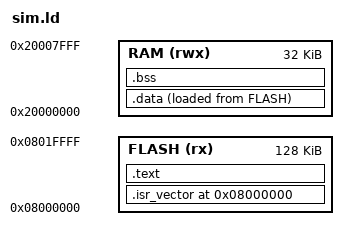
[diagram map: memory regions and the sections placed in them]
MEMORY
{
    FLASH (rx)  : ORIGIN = 0x08000000, LENGTH = 128K
    RAM   (rwx) : ORIGIN = 0x20000000, LENGTH = 32K
}

ENTRY(main)

SECTIONS
{
    . = 0x08000000;

    .isr_vector :
    {
        LONG(0x20001000)
        LONG(main)
        FILL(0x00000000)
        . = 0x200;
    } > FLASH

    .text :
    {
        *(.text)
        *(.text*)
        *(.rodata)
        *(.rodata*)
        . = ALIGN(4);
        _etext = .;
    } > FLASH

    .data :
    {
        _sdata = .;
        *(.data)
        *(.data*)
        . = ALIGN(4);
        _edata = .;
    } > RAM AT > FLASH

    .bss :
    {
        _sbss = .;
        *(.bss)
        *(.bss*)
        *(COMMON)
        . = ALIGN(4);
        _ebss = .;
    } > RAM

    _estack = 0x20002000;

    /DISCARD/ :
    {
        *(.note*)
        *(.comment*)
        *(.eh_frame*)
    }
}
